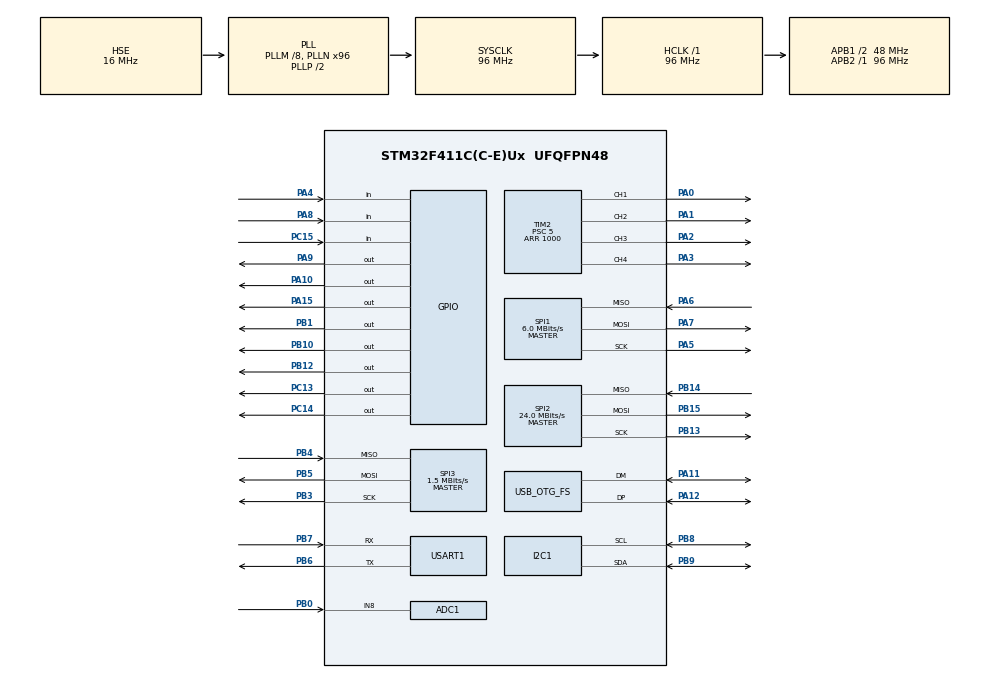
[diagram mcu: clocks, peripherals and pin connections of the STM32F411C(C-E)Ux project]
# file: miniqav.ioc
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ADC1.Channel-0\#ChannelRegularConversion=ADC_CHANNEL_8
ADC1.ClockPrescaler=ADC_CLOCK_SYNC_PCLK_DIV8
ADC1.NbrOfConversionFlag=1
ADC1.Rank-0\#ChannelRegularConversion=1
ADC1.SamplingTime-0\#ChannelRegularConversion=ADC_SAMPLETIME_3CYCLES
ADC1.master=1
FATFS._USE_LABEL=1
FREERTOS.HEAP_NUMBER=1
FREERTOS.INCLUDE_eTaskGetState=1
FREERTOS.INCLUDE_vTaskDelayUntil=1
FREERTOS.INCLUDE_xTaskGetCurrentTaskHandle=1
FREERTOS.Tasks01=defaultTask,0,128,StartDefaultTask,Default,NULL
FREERTOS.configMINIMAL_STACK_SIZE=128
FREERTOS.configTOTAL_HEAP_SIZE=4096
Mcu.Family=STM32F4
Mcu.Name=STM32F411C(C-E)Ux
Mcu.Package=UFQFPN48
NVIC.OTG_FS_IRQn=true\:5\:0\:false\:false\:true\:true\:true\:true
NVIC.PriorityGroup=NVIC_PRIORITYGROUP_4
PA0-WKUP.Signal=S_TIM2_CH1_ETR
PA1.Signal=S_TIM2_CH2
PA10.GPIO_PuPd=GPIO_NOPULL
PA10.GPIO_Speed=GPIO_SPEED_FREQ_MEDIUM
PA10.PinState=GPIO_PIN_RESET
PA10.Signal=GPIO_Output
PA11.Mode=Device_Only
PA11.Signal=USB_OTG_FS_DM
PA12.Mode=Device_Only
PA12.Signal=USB_OTG_FS_DP
PA13.Mode=Serial_Wire
PA13.Signal=SYS_JTMS-SWDIO
PA14.Mode=Serial_Wire
PA14.Signal=SYS_JTCK-SWCLK
PA15.GPIO_PuPd=GPIO_PULLUP
PA15.GPIO_Speed=GPIO_SPEED_FREQ_HIGH
PA15.PinState=GPIO_PIN_SET
PA15.Signal=GPIO_Output
PA2.Signal=S_TIM2_CH3
PA3.Signal=S_TIM2_CH4
PA4.GPIO_PuPd=GPIO_PULLUP
PA4.Signal=GPIO_Input
PA5.Mode=Full_Duplex_Master
PA5.Signal=SPI1_SCK
PA6.Mode=Full_Duplex_Master
PA6.Signal=SPI1_MISO
PA7.Mode=Full_Duplex_Master
PA7.Signal=SPI1_MOSI
PA8.GPIO_PuPd=GPIO_PULLDOWN
PA8.Signal=GPIO_Input
PA9.GPIO_PuPd=GPIO_NOPULL
PA9.GPIO_Speed=GPIO_SPEED_FREQ_MEDIUM
PA9.PinState=GPIO_PIN_RESET
PA9.Signal=GPIO_Output
PB0.Signal=ADCx_IN8
PB1.GPIO_PuPd=GPIO_PULLUP
PB1.GPIO_Speed=GPIO_SPEED_FREQ_HIGH
PB1.PinState=GPIO_PIN_SET
PB1.Signal=GPIO_Output
PB10.GPIO_ModeDefaultOutputPP=GPIO_MODE_OUTPUT_PP
PB10.GPIO_PuPd=GPIO_PULLUP
PB10.GPIO_Speed=GPIO_SPEED_FREQ_HIGH
PB10.PinState=GPIO_PIN_SET
PB10.Signal=GPIO_Output
PB12.GPIO_PuPd=GPIO_PULLUP
PB12.GPIO_Speed=GPIO_SPEED_FREQ_HIGH
PB12.PinState=GPIO_PIN_SET
PB12.Signal=GPIO_Output
PB13.Mode=Full_Duplex_Master
PB13.Signal=SPI2_SCK
PB14.Mode=Full_Duplex_Master
PB14.Signal=SPI2_MISO
PB15.Mode=Full_Duplex_Master
PB15.Signal=SPI2_MOSI
PB3.Mode=Full_Duplex_Master
PB3.Signal=SPI3_SCK
PB4.Mode=Full_Duplex_Master
PB4.Signal=SPI3_MISO
PB5.Mode=Full_Duplex_Master
PB5.Signal=SPI3_MOSI
PB6.Mode=Asynchronous
PB6.Signal=USART1_TX
PB7.Mode=Asynchronous
PB7.Signal=USART1_RX
PB8.Mode=I2C
PB8.Signal=I2C1_SCL
PB9.Mode=I2C
PB9.Signal=I2C1_SDA
PC13-ANTI_TAMP.GPIO_PuPd=GPIO_PULLUP
PC13-ANTI_TAMP.GPIO_Speed=GPIO_SPEED_FREQ_LOW
PC13-ANTI_TAMP.PinState=GPIO_PIN_SET
PC13-ANTI_TAMP.Signal=GPIO_Output
PC14-OSC32_IN.GPIO_PuPd=GPIO_PULLDOWN
PC14-OSC32_IN.PinState=GPIO_PIN_SET
PC14-OSC32_IN.Signal=GPIO_Output
PC15-OSC32_OUT.GPIO_PuPd=GPIO_NOPULL
PC15-OSC32_OUT.Signal=GPIO_Input
PH0\ -\ OSC_IN.Mode=HSE-External-Oscillator
PH0\ -\ OSC_IN.Signal=RCC_OSC_IN
PH1\ -\ OSC_OUT.Mode=HSE-External-Oscillator
PH1\ -\ OSC_OUT.Signal=RCC_OSC_OUT
ProjectManager.HeapSize=0x2000
ProjectManager.StackSize=0x4000
ProjectManager.TargetToolchain=MDK-ARM V5
RCC.48MHZClocksFreq_Value=48000000
RCC.AHBFreq_Value=96000000
RCC.APB1CLKDivider=RCC_HCLK_DIV2
RCC.APB1Freq_Value=48000000
RCC.APB1TimFreq_Value=96000000
RCC.APB2Freq_Value=96000000
RCC.APB2TimFreq_Value=96000000
RCC.CortexFreq_Value=96000000
RCC.HCLKFreq_Value=96000000
RCC.HSE_VALUE=16000000
RCC.HSI_VALUE=16000000
RCC.LSE_VALUE=32768
RCC.PLLM=8
RCC.PLLN=96
RCC.SYSCLKFreq_VALUE=96000000
RCC.SYSCLKSource=RCC_SYSCLKSOURCE_PLLCLK
RCC.VCOOutputFreq_Value=192000000
RCC.VDD_VALUE=3
SH.ADCx_IN8.0=ADC1_IN8,IN8
SH.S_TIM2_CH1_ETR.0=TIM2_CH1,PWM Generation1 CH1
SH.S_TIM2_CH2.0=TIM2_CH2,PWM Generation2 CH2
SH.S_TIM2_CH3.0=TIM2_CH3,PWM Generation3 CH3
SH.S_TIM2_CH4.0=TIM2_CH4,PWM Generation4 CH4
SPI1.BaudRatePrescaler=SPI_BAUDRATEPRESCALER_16
SPI1.CalculateBaudRate=6.0 MBits/s
SPI1.Direction=SPI_DIRECTION_2LINES
SPI1.Mode=SPI_MODE_MASTER
SPI1.VirtualType=VM_MASTER
SPI2.BaudRatePrescaler=SPI_BAUDRATEPRESCALER_2
SPI2.CalculateBaudRate=24.0 MBits/s
SPI2.Direction=SPI_DIRECTION_2LINES
SPI2.Mode=SPI_MODE_MASTER
SPI2.VirtualType=VM_MASTER
SPI3.BaudRatePrescaler=SPI_BAUDRATEPRESCALER_32
SPI3.CalculateBaudRate=1.5 MBits/s
SPI3.Direction=SPI_DIRECTION_2LINES
SPI3.Mode=SPI_MODE_MASTER
SPI3.VirtualType=VM_MASTER
TIM2.Channel-PWM\ Generation1\ CH1=TIM_CHANNEL_1
TIM2.Channel-PWM\ Generation2\ CH2=TIM_CHANNEL_2
TIM2.Channel-PWM\ Generation3\ CH3=TIM_CHANNEL_3
TIM2.Channel-PWM\ Generation4\ CH4=TIM_CHANNEL_4
TIM2.CounterMode=TIM_COUNTERMODE_DOWN
TIM2.OCPolarity_1=TIM_OCPOLARITY_HIGH
TIM2.OCPolarity_2=TIM_OCPOLARITY_HIGH
TIM2.OCPolarity_3=TIM_OCPOLARITY_HIGH
TIM2.OCPolarity_4=TIM_OCPOLARITY_HIGH
TIM2.Period=1000
TIM2.Prescaler=5
TIM2.Pulse-PWM\ Generation1\ CH1=40
TIM2.Pulse-PWM\ Generation2\ CH2=40
TIM2.Pulse-PWM\ Generation3\ CH3=40
TIM2.Pulse-PWM\ Generation4\ CH4=40
USART1.VirtualMode=VM_ASYNC
USB_DEVICE.CLASS_NAME_FS=MSC
USB_DEVICE.MANUFACTURER_STRING=miniqav
USB_DEVICE.PRODUCT_STRING_MSC_FS=miniqav_disk
USB_DEVICE.VirtualMode=Msc
USB_DEVICE.VirtualModeFS=Msc_FS
USB_OTG_FS.VirtualMode=Device_Only
VP_FATFS_VS_Generic.Mode=User_defined
VP_FREERTOS_VS_CMSIS_V1.Mode=CMSIS_V1
VP_USB_DEVICE_VS_USB_DEVICE_MSC_FS.Mode=MSC_FS
board=custom

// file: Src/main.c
/* USER CODE BEGIN Header */
/**
  ******************************************************************************
  * @file           : main.c
  * @brief          : Main program body
  ******************************************************************************
  * @attention
  *
  * <h2><center>&copy; Copyright (c) 2019 STMicroelectronics.
  * All rights reserved.</center></h2>
  *
  * This software component is licensed by ST under Ultimate Liberty license
  * SLA0044, the "License"; You may not use this file except in compliance with
  * the License. You may obtain a copy of the License at:
  *                             www.st.com/SLA0044
  *
  ******************************************************************************
  */
/* USER CODE END Header */

#include "main.h"
#include "cmsis_os.h"
#include "fatfs.h"
#include "usb_device.h"

/* USER CODE BEGIN Includes */
#include "fs.h"
/* USER CODE END Includes */

ADC_HandleTypeDef hadc1;

I2C_HandleTypeDef hi2c1;

SPI_HandleTypeDef hspi1;
SPI_HandleTypeDef hspi2;
SPI_HandleTypeDef hspi3;

TIM_HandleTypeDef htim2;

UART_HandleTypeDef huart1;

osThreadId defaultTaskHandle;

void SystemClock_Config(void);
static void MX_GPIO_Init(void);
static void MX_ADC1_Init(void);
static void MX_I2C1_Init(void);
static void MX_SPI1_Init(void);
static void MX_SPI2_Init(void);
static void MX_SPI3_Init(void);
static void MX_TIM2_Init(void);
static void MX_USART1_UART_Init(void);
void StartDefaultTask(void const * argument);

int main(void)
{

  /* MCU Configuration--------------------------------------------------------*/

  /* Reset of all peripherals, Initializes the Flash interface and the Systick. */
  HAL_Init();

  /* Configure the system clock */
  SystemClock_Config();

  /* Initialize all configured peripherals */
  MX_GPIO_Init();
  MX_ADC1_Init();
  MX_I2C1_Init();
  MX_SPI1_Init();
  MX_SPI2_Init();
  MX_SPI3_Init();
  MX_TIM2_Init();
  MX_USART1_UART_Init();

  /* Create the thread(s) */
  /* definition and creation of defaultTask */
  osThreadDef(defaultTask, StartDefaultTask, osPriorityNormal, 0, 128);
  defaultTaskHandle = osThreadCreate(osThread(defaultTask), NULL);

  /* USER CODE BEGIN RTOS_THREADS */
  /* add threads, ... */
	/* system init */
	fs_system_initialization();
  /* USER CODE END RTOS_THREADS */

  /* Start scheduler */
  osKernelStart();

  /* We should never get here as control is now taken by the scheduler */

  /* Infinite loop */
  while (1)
  {

  }
}

void SystemClock_Config(void)
{
  RCC_OscInitTypeDef RCC_OscInitStruct = {0};
  RCC_ClkInitTypeDef RCC_ClkInitStruct = {0};

  /** Configure the main internal regulator output voltage
  */
  __HAL_RCC_PWR_CLK_ENABLE();
  __HAL_PWR_VOLTAGESCALING_CONFIG(PWR_REGULATOR_VOLTAGE_SCALE1);
  /** Initializes the CPU, AHB and APB busses clocks
  */
  RCC_OscInitStruct.OscillatorType = RCC_OSCILLATORTYPE_HSE;
  RCC_OscInitStruct.HSEState = RCC_HSE_ON;
  RCC_OscInitStruct.PLL.PLLState = RCC_PLL_ON;
  RCC_OscInitStruct.PLL.PLLSource = RCC_PLLSOURCE_HSE;
  RCC_OscInitStruct.PLL.PLLM = 8;
  RCC_OscInitStruct.PLL.PLLN = 96;
  RCC_OscInitStruct.PLL.PLLP = RCC_PLLP_DIV2;
  RCC_OscInitStruct.PLL.PLLQ = 4;
  if (HAL_RCC_OscConfig(&RCC_OscInitStruct) != HAL_OK)
  {
    Error_Handler();
  }
  /** Initializes the CPU, AHB and APB busses clocks
  */
  RCC_ClkInitStruct.ClockType = RCC_CLOCKTYPE_HCLK|RCC_CLOCKTYPE_SYSCLK
                              |RCC_CLOCKTYPE_PCLK1|RCC_CLOCKTYPE_PCLK2;
  RCC_ClkInitStruct.SYSCLKSource = RCC_SYSCLKSOURCE_PLLCLK;
  RCC_ClkInitStruct.AHBCLKDivider = RCC_SYSCLK_DIV1;
  RCC_ClkInitStruct.APB1CLKDivider = RCC_HCLK_DIV2;
  RCC_ClkInitStruct.APB2CLKDivider = RCC_HCLK_DIV1;

  if (HAL_RCC_ClockConfig(&RCC_ClkInitStruct, FLASH_LATENCY_3) != HAL_OK)
  {
    Error_Handler();
  }
}

static void MX_ADC1_Init(void)
{

  ADC_ChannelConfTypeDef sConfig = {0};

  /** Configure the global features of the ADC (Clock, Resolution, Data Alignment and number of conversion)
  */
  hadc1.Instance = ADC1;
  hadc1.Init.ClockPrescaler = ADC_CLOCK_SYNC_PCLK_DIV8;
  hadc1.Init.Resolution = ADC_RESOLUTION_12B;
  hadc1.Init.ScanConvMode = DISABLE;
  hadc1.Init.ContinuousConvMode = DISABLE;
  hadc1.Init.DiscontinuousConvMode = DISABLE;
  hadc1.Init.ExternalTrigConvEdge = ADC_EXTERNALTRIGCONVEDGE_NONE;
  hadc1.Init.ExternalTrigConv = ADC_SOFTWARE_START;
  hadc1.Init.DataAlign = ADC_DATAALIGN_RIGHT;
  hadc1.Init.NbrOfConversion = 1;
  hadc1.Init.DMAContinuousRequests = DISABLE;
  hadc1.Init.EOCSelection = ADC_EOC_SINGLE_CONV;
  if (HAL_ADC_Init(&hadc1) != HAL_OK)
  {
    Error_Handler();
  }
  /** Configure for the selected ADC regular channel its corresponding rank in the sequencer and its sample time.
  */
  sConfig.Channel = ADC_CHANNEL_8;
  sConfig.Rank = 1;
  sConfig.SamplingTime = ADC_SAMPLETIME_3CYCLES;
  if (HAL_ADC_ConfigChannel(&hadc1, &sConfig) != HAL_OK)
  {
    Error_Handler();
  }

}

static void MX_I2C1_Init(void)
{

  hi2c1.Instance = I2C1;
  hi2c1.Init.ClockSpeed = 100000;
  hi2c1.Init.DutyCycle = I2C_DUTYCYCLE_2;
  hi2c1.Init.OwnAddress1 = 0;
  hi2c1.Init.AddressingMode = I2C_ADDRESSINGMODE_7BIT;
  hi2c1.Init.DualAddressMode = I2C_DUALADDRESS_DISABLE;
  hi2c1.Init.OwnAddress2 = 0;
  hi2c1.Init.GeneralCallMode = I2C_GENERALCALL_DISABLE;
  hi2c1.Init.NoStretchMode = I2C_NOSTRETCH_DISABLE;
  if (HAL_I2C_Init(&hi2c1) != HAL_OK)
  {
    Error_Handler();
  }

}

static void MX_SPI1_Init(void)
{

  /* SPI1 parameter configuration*/
  hspi1.Instance = SPI1;
  hspi1.Init.Mode = SPI_MODE_MASTER;
  hspi1.Init.Direction = SPI_DIRECTION_2LINES;
  hspi1.Init.DataSize = SPI_DATASIZE_8BIT;
  hspi1.Init.CLKPolarity = SPI_POLARITY_LOW;
  hspi1.Init.CLKPhase = SPI_PHASE_1EDGE;
  hspi1.Init.NSS = SPI_NSS_SOFT;
  hspi1.Init.BaudRatePrescaler = SPI_BAUDRATEPRESCALER_16;
  hspi1.Init.FirstBit = SPI_FIRSTBIT_MSB;
  hspi1.Init.TIMode = SPI_TIMODE_DISABLE;
  hspi1.Init.CRCCalculation = SPI_CRCCALCULATION_DISABLE;
  hspi1.Init.CRCPolynomial = 10;
  if (HAL_SPI_Init(&hspi1) != HAL_OK)
  {
    Error_Handler();
  }

}

static void MX_SPI2_Init(void)
{

  /* SPI2 parameter configuration*/
  hspi2.Instance = SPI2;
  hspi2.Init.Mode = SPI_MODE_MASTER;
  hspi2.Init.Direction = SPI_DIRECTION_2LINES;
  hspi2.Init.DataSize = SPI_DATASIZE_8BIT;
  hspi2.Init.CLKPolarity = SPI_POLARITY_LOW;
  hspi2.Init.CLKPhase = SPI_PHASE_1EDGE;
  hspi2.Init.NSS = SPI_NSS_SOFT;
  hspi2.Init.BaudRatePrescaler = SPI_BAUDRATEPRESCALER_2;
  hspi2.Init.FirstBit = SPI_FIRSTBIT_MSB;
  hspi2.Init.TIMode = SPI_TIMODE_DISABLE;
  hspi2.Init.CRCCalculation = SPI_CRCCALCULATION_DISABLE;
  hspi2.Init.CRCPolynomial = 10;
  if (HAL_SPI_Init(&hspi2) != HAL_OK)
  {
    Error_Handler();
  }

}

static void MX_SPI3_Init(void)
{

  /* SPI3 parameter configuration*/
  hspi3.Instance = SPI3;
  hspi3.Init.Mode = SPI_MODE_MASTER;
  hspi3.Init.Direction = SPI_DIRECTION_2LINES;
  hspi3.Init.DataSize = SPI_DATASIZE_8BIT;
  hspi3.Init.CLKPolarity = SPI_POLARITY_LOW;
  hspi3.Init.CLKPhase = SPI_PHASE_1EDGE;
  hspi3.Init.NSS = SPI_NSS_SOFT;
  hspi3.Init.BaudRatePrescaler = SPI_BAUDRATEPRESCALER_32;
  hspi3.Init.FirstBit = SPI_FIRSTBIT_MSB;
  hspi3.Init.TIMode = SPI_TIMODE_DISABLE;
  hspi3.Init.CRCCalculation = SPI_CRCCALCULATION_DISABLE;
  hspi3.Init.CRCPolynomial = 10;
  if (HAL_SPI_Init(&hspi3) != HAL_OK)
  {
    Error_Handler();
  }

}

static void MX_TIM2_Init(void)
{

  TIM_MasterConfigTypeDef sMasterConfig = {0};
  TIM_OC_InitTypeDef sConfigOC = {0};

  htim2.Instance = TIM2;
  htim2.Init.Prescaler = 5;
  htim2.Init.CounterMode = TIM_COUNTERMODE_UP;
  htim2.Init.Period = 1000 - 1 ;
  htim2.Init.ClockDivision = TIM_CLOCKDIVISION_DIV1;
  htim2.Init.AutoReloadPreload = TIM_AUTORELOAD_PRELOAD_DISABLE;
  if (HAL_TIM_PWM_Init(&htim2) != HAL_OK)
  {
    Error_Handler();
  }
  sMasterConfig.MasterOutputTrigger = TIM_TRGO_RESET;
  sMasterConfig.MasterSlaveMode = TIM_MASTERSLAVEMODE_DISABLE;
  if (HAL_TIMEx_MasterConfigSynchronization(&htim2, &sMasterConfig) != HAL_OK)
  {
    Error_Handler();
  }
  sConfigOC.OCMode = TIM_OCMODE_PWM1;
  sConfigOC.Pulse = 40;
  sConfigOC.OCPolarity = TIM_OCPOLARITY_HIGH;
  sConfigOC.OCFastMode = TIM_OCFAST_DISABLE;
  if (HAL_TIM_PWM_ConfigChannel(&htim2, &sConfigOC, TIM_CHANNEL_1) != HAL_OK)
  {
    Error_Handler();
  }
  if (HAL_TIM_PWM_ConfigChannel(&htim2, &sConfigOC, TIM_CHANNEL_2) != HAL_OK)
  {
    Error_Handler();
  }
  if (HAL_TIM_PWM_ConfigChannel(&htim2, &sConfigOC, TIM_CHANNEL_3) != HAL_OK)
  {
    Error_Handler();
  }
  if (HAL_TIM_PWM_ConfigChannel(&htim2, &sConfigOC, TIM_CHANNEL_4) != HAL_OK)
  {
    Error_Handler();
  }
  /* USER CODE BEGIN TIM2_Init 2 */
//  HAL_TIM_PWM_Start(&htim2,TIM_CHANNEL_1);
//	HAL_TIM_PWM_Start(&htim2,TIM_CHANNEL_2);
//	HAL_TIM_PWM_Start(&htim2,TIM_CHANNEL_3);
//	HAL_TIM_PWM_Start(&htim2,TIM_CHANNEL_4);
  /* USER CODE END TIM2_Init 2 */
  HAL_TIM_MspPostInit(&htim2);

}

static void MX_USART1_UART_Init(void)
{

  huart1.Instance = USART1;
  huart1.Init.BaudRate = 115200;
  huart1.Init.WordLength = UART_WORDLENGTH_8B;
  huart1.Init.StopBits = UART_STOPBITS_1;
  huart1.Init.Parity = UART_PARITY_NONE;
  huart1.Init.Mode = UART_MODE_TX_RX;
  huart1.Init.HwFlowCtl = UART_HWCONTROL_NONE;
  huart1.Init.OverSampling = UART_OVERSAMPLING_16;
  if (HAL_UART_Init(&huart1) != HAL_OK)
  {
    Error_Handler();
  }

}

static void MX_GPIO_Init(void)
{
  GPIO_InitTypeDef GPIO_InitStruct = {0};

  /* GPIO Ports Clock Enable */
  __HAL_RCC_GPIOC_CLK_ENABLE();
  __HAL_RCC_GPIOH_CLK_ENABLE();
  __HAL_RCC_GPIOA_CLK_ENABLE();
  __HAL_RCC_GPIOB_CLK_ENABLE();

  /*Configure GPIO pin Output Level */
  HAL_GPIO_WritePin(GPIOC, GPIO_PIN_13|GPIO_PIN_14, GPIO_PIN_SET);

  /*Configure GPIO pin Output Level */
  HAL_GPIO_WritePin(GPIOB, GPIO_PIN_1|GPIO_PIN_10|GPIO_PIN_12, GPIO_PIN_SET);

  /*Configure GPIO pin Output Level */
  HAL_GPIO_WritePin(GPIOA, GPIO_PIN_9|GPIO_PIN_10, GPIO_PIN_RESET);

  /*Configure GPIO pin Output Level */
  HAL_GPIO_WritePin(GPIOA, GPIO_PIN_15, GPIO_PIN_SET);

  /*Configure GPIO pin : PC13 */
  GPIO_InitStruct.Pin = GPIO_PIN_13;
  GPIO_InitStruct.Mode = GPIO_MODE_OUTPUT_PP;
  GPIO_InitStruct.Pull = GPIO_PULLUP;
  GPIO_InitStruct.Speed = GPIO_SPEED_FREQ_LOW;
  HAL_GPIO_Init(GPIOC, &GPIO_InitStruct);

  /*Configure GPIO pin : PC14 */
  GPIO_InitStruct.Pin = GPIO_PIN_14;
  GPIO_InitStruct.Mode = GPIO_MODE_OUTPUT_PP;
  GPIO_InitStruct.Pull = GPIO_PULLDOWN;
  GPIO_InitStruct.Speed = GPIO_SPEED_FREQ_LOW;
  HAL_GPIO_Init(GPIOC, &GPIO_InitStruct);

  /*Configure GPIO pin : PC15 */
  GPIO_InitStruct.Pin = GPIO_PIN_15;
  GPIO_InitStruct.Mode = GPIO_MODE_INPUT;
  GPIO_InitStruct.Pull = GPIO_NOPULL;
  HAL_GPIO_Init(GPIOC, &GPIO_InitStruct);

  /*Configure GPIO pin : PA4 */
  GPIO_InitStruct.Pin = GPIO_PIN_4;
  GPIO_InitStruct.Mode = GPIO_MODE_INPUT;
  GPIO_InitStruct.Pull = GPIO_PULLUP;
  HAL_GPIO_Init(GPIOA, &GPIO_InitStruct);

  /*Configure GPIO pins : PB1 PB10 PB12 */
  GPIO_InitStruct.Pin = GPIO_PIN_1|GPIO_PIN_10|GPIO_PIN_12;
  GPIO_InitStruct.Mode = GPIO_MODE_OUTPUT_PP;
  GPIO_InitStruct.Pull = GPIO_PULLUP;
  GPIO_InitStruct.Speed = GPIO_SPEED_FREQ_HIGH;
  HAL_GPIO_Init(GPIOB, &GPIO_InitStruct);

  /*Configure GPIO pin : PA8 */
  GPIO_InitStruct.Pin = GPIO_PIN_8;
  GPIO_InitStruct.Mode = GPIO_MODE_INPUT;
  GPIO_InitStruct.Pull = GPIO_PULLDOWN;
  HAL_GPIO_Init(GPIOA, &GPIO_InitStruct);

  /*Configure GPIO pins : PA9 PA10 */
  GPIO_InitStruct.Pin = GPIO_PIN_9|GPIO_PIN_10;
  GPIO_InitStruct.Mode = GPIO_MODE_OUTPUT_PP;
  GPIO_InitStruct.Pull = GPIO_NOPULL;
  GPIO_InitStruct.Speed = GPIO_SPEED_FREQ_MEDIUM;
  HAL_GPIO_Init(GPIOA, &GPIO_InitStruct);

  /*Configure GPIO pin : PA15 */
  GPIO_InitStruct.Pin = GPIO_PIN_15;
  GPIO_InitStruct.Mode = GPIO_MODE_OUTPUT_PP;
  GPIO_InitStruct.Pull = GPIO_PULLUP;
  GPIO_InitStruct.Speed = GPIO_SPEED_FREQ_HIGH;
  HAL_GPIO_Init(GPIOA, &GPIO_InitStruct);

}

void StartDefaultTask(void const * argument)
{
  /* init code for FATFS */
  MX_FATFS_Init();

  /* init code for USB_DEVICE */
  MX_USB_DEVICE_Init();

  for(;;)
  {
    osDelay(1);
  }
}

void Error_Handler(void)
{
}

/************************ (C) COPYRIGHT STMicroelectronics *****END OF FILE****/
